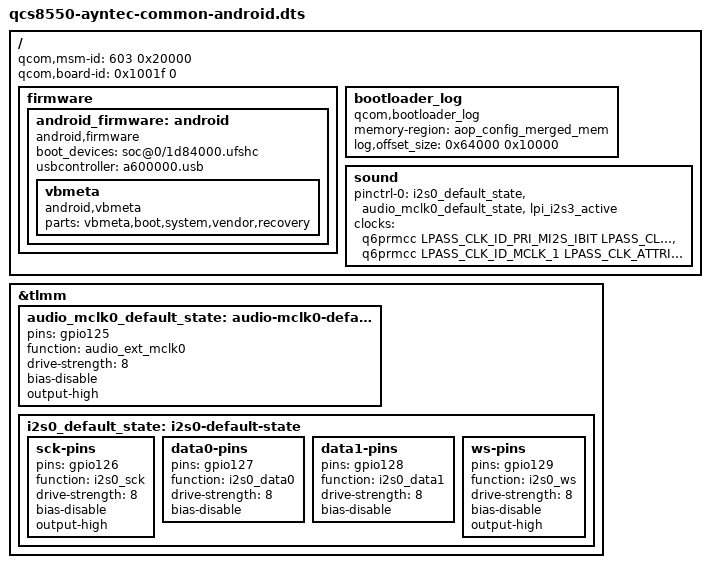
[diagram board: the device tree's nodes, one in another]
// SPDX-License-Identifier: BSD-3-Clause
// SPDX-FileCopyrightText: The LineageOS Project

#define scm qcom_scm

#include "qcs8550-ayntec-common.dts"

/ {
	qcom,msm-id = <603 0x20000>;
	qcom,board-id = <0x1001f 0>;

	firmware {
		android_firmware: android {
			compatible = "android,firmware";
			boot_devices = "soc@0/1d84000.ufshc";
			usbcontroller = "a600000.usb";

			vbmeta {
				compatible = "android,vbmeta";
				parts = "vbmeta,boot,system,vendor,recovery";
			};
		};
	};

	bootloader_log {
		compatible = "qcom,bootloader_log";
		memory-region = <&aop_config_merged_mem>;
		log,offset_size = <0x64000 0x10000>;
	};

	sound {
		pinctrl-0 = <&i2s0_default_state>, <&audio_mclk0_default_state>, <&lpi_i2s3_active>;

		clocks = <&q6prmcc LPASS_CLK_ID_PRI_MI2S_IBIT LPASS_CLK_ATTRIBUTE_COUPLE_NO>,
			 <&q6prmcc LPASS_CLK_ID_MCLK_1 LPASS_CLK_ATTRIBUTE_COUPLE_NO>;
		clock-names = "primary-mi2s",
			      "primary-mclk";
	};
};

&tlmm {
	audio_mclk0_default_state: audio-mclk0-default-state {
		pins = "gpio125";
		function = "audio_ext_mclk0";
		drive-strength = <8>;
		bias-disable;
		output-high;
	};

	i2s0_default_state: i2s0-default-state {
		sck-pins {
			pins = "gpio126";
			function = "i2s0_sck";
			drive-strength = <8>;
			bias-disable;
			output-high;
		};

		data0-pins {
			pins = "gpio127";
			function = "i2s0_data0";
			drive-strength = <8>;
			bias-disable;
		};

		data1-pins {
			pins = "gpio128";
			function = "i2s0_data1";
			drive-strength = <8>;
			bias-disable;
		};

		ws-pins {
			pins = "gpio129";
			function = "i2s0_ws";
			drive-strength = <8>;
			bias-disable;
			output-high;
		};
	};
};
